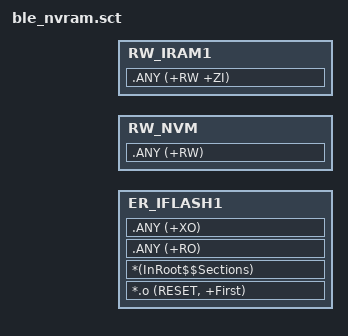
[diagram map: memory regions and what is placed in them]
#! armcc -E -I .\..\

#include "sct_config.h"

#include "./RTE/_Flash_Debug/RTE_Components.h"

LR_IFLASH1 IFLASH_start__ IFLASH_size__  {    ; load region size_region
  ER_IFLASH1 IFLASH_start__ CODE_size__  {    ; load address = execution address
   *.o (RESET, +First)
   *(InRoot$$Sections)
   .ANY (+RO)
   .ANY (+XO)
  }
  
  RW_NVM  PAL_NVM_DB_START__  PAL_NVM_SIZE  { ; RW DATA
    .ANY (+RW)
  }
	
  RW_IRAM1 IRAM_start__ IRAM_size__  {  ; RW data
   .ANY (+RW +ZI)
  }
  
}
	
